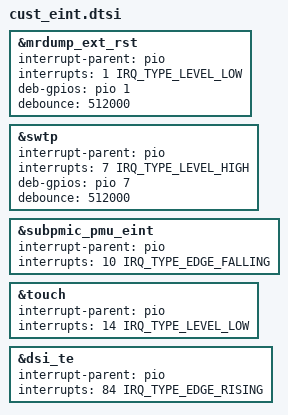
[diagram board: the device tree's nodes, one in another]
/*
 * Generated by MTK SP DrvGen Version: 3.5.160809 for MT6833.
 * 2023-03-11 17:22:12
 * Do Not Modify The File.
 * Copyright Mediatek Inc. (c) 2016.
*/

/*************************
 * EINT DTSI File
*************************/

#include <dt-bindings/interrupt-controller/irq.h>
#include <dt-bindings/interrupt-controller/arm-gic.h>

&mrdump_ext_rst {
	interrupt-parent = <&pio>;
	interrupts = <1 IRQ_TYPE_LEVEL_LOW>;
	deb-gpios = <&pio 1 0>;
	debounce = <512000>;
	status = "okay";
};

&swtp {
	interrupt-parent = <&pio>;
	interrupts = <7 IRQ_TYPE_LEVEL_HIGH>;
	deb-gpios = <&pio 7 0>;
	debounce = <512000>;
	status = "okay";
};

&subpmic_pmu_eint {
	interrupt-parent = <&pio>;
	interrupts = <10 IRQ_TYPE_EDGE_FALLING>;
	status = "okay";
};

&touch {
	interrupt-parent = <&pio>;
	interrupts = <14 IRQ_TYPE_LEVEL_LOW>;
	status = "okay";
};

&dsi_te {
	interrupt-parent = <&pio>;
	interrupts = <84 IRQ_TYPE_EDGE_RISING>;
	status = "okay";
};

